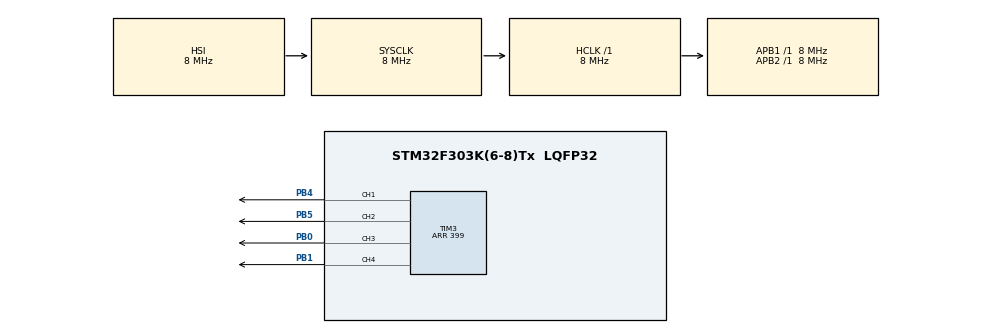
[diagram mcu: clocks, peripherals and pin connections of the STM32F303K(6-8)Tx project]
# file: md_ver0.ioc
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Mcu.Family=STM32F3
Mcu.Name=STM32F303K(6-8)Tx
Mcu.Package=LQFP32
NVIC.PriorityGroup=NVIC_PRIORITYGROUP_4
PB0.Signal=S_TIM3_CH3
PB1.Signal=S_TIM3_CH4
PB4.Signal=S_TIM3_CH1
PB5.Signal=S_TIM3_CH2
ProjectManager.HeapSize=0x200
ProjectManager.StackSize=0x400
ProjectManager.TargetToolchain=STM32CubeIDE
RCC.AHBFreq_Value=8000000
RCC.APB1Freq_Value=8000000
RCC.APB2Freq_Value=8000000
RCC.CortexFreq_Value=8000000
RCC.HSE_VALUE=8000000
RCC.HSI_VALUE=8000000
RCC.SYSCLKFreq_VALUE=8000000
SH.S_TIM3_CH1.0=TIM3_CH1,PWM Generation1 CH1
SH.S_TIM3_CH2.0=TIM3_CH2,PWM Generation2 CH2
SH.S_TIM3_CH3.0=TIM3_CH3,PWM Generation3 CH3
SH.S_TIM3_CH4.0=TIM3_CH4,PWM Generation4 CH4
TIM3.AutoReloadPreload=TIM_AUTORELOAD_PRELOAD_ENABLE
TIM3.Channel-PWM\ Generation1\ CH1=TIM_CHANNEL_1
TIM3.Channel-PWM\ Generation2\ CH2=TIM_CHANNEL_2
TIM3.Channel-PWM\ Generation3\ CH3=TIM_CHANNEL_3
TIM3.Channel-PWM\ Generation4\ CH4=TIM_CHANNEL_4
TIM3.CounterMode=TIM_COUNTERMODE_CENTERALIGNED3
TIM3.OCMode_PWM-PWM\ Generation3\ CH3=TIM_OCMODE_PWM2
TIM3.OCMode_PWM-PWM\ Generation4\ CH4=TIM_OCMODE_PWM1
TIM3.Period=399
board=custom

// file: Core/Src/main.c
/* USER CODE BEGIN Header */
/**
  ******************************************************************************
  * @file           : main.c
  * @brief          : Main program body
  ******************************************************************************
  * @attention
  *
  * Copyright (c) 2024 STMicroelectronics.
  * All rights reserved.
  *
  * This software is licensed under terms that can be found in the LICENSE file
  * in the root directory of this software component.
  * If no LICENSE file comes with this software, it is provided AS-IS.
  *
  ******************************************************************************
  */
/* USER CODE END Header */
#include "main.h"
#include "tim.h"
#include "gpio.h"

void SystemClock_Config(void);

int main(void)
{

  /* MCU Configuration--------------------------------------------------------*/

  /* Reset of all peripherals, Initializes the Flash interface and the Systick. */
  HAL_Init();

  /* Configure the system clock */
  SystemClock_Config();

  /* Initialize all configured peripherals */
  MX_GPIO_Init();
  MX_TIM3_Init();
  /* USER CODE BEGIN 2 */
//
//  int high = 300;
//  int low = 100;

  HAL_TIM_PWM_Start(&htim3, TIM_CHANNEL_1);
  HAL_TIM_PWM_Start(&htim3, TIM_CHANNEL_2);
  HAL_TIM_PWM_Start(&htim3, TIM_CHANNEL_3);
  HAL_TIM_PWM_Start(&htim3, TIM_CHANNEL_4);

  __HAL_TIM_SET_COMPARE(&htim3, TIM_CHANNEL_1, 0);
  __HAL_TIM_SET_COMPARE(&htim3, TIM_CHANNEL_2, 0);
  __HAL_TIM_SET_COMPARE(&htim3, TIM_CHANNEL_3, 0);
  __HAL_TIM_SET_COMPARE(&htim3, TIM_CHANNEL_3, 0);

  /* USER CODE END 2 */

  /* Infinite loop */
  /* USER CODE BEGIN WHILE */
  while (1)
  {
	  __HAL_TIM_SET_COMPARE(&htim3, TIM_CHANNEL_1, 0);
	  __HAL_TIM_SET_COMPARE(&htim3, TIM_CHANNEL_2, 399);
	  __HAL_TIM_SET_COMPARE(&htim3, TIM_CHANNEL_3, 60);
	  __HAL_TIM_SET_COMPARE(&htim3, TIM_CHANNEL_4, 40);

	  HAL_Delay(2000);
//
//	  __HAL_TIM_SET_COMPARE(&htim3, TIM_CHANNEL_1, 0);
//	  __HAL_TIM_SET_COMPARE(&htim3, TIM_CHANNEL_2, 80);
//	  __HAL_TIM_SET_COMPARE(&htim3, TIM_CHANNEL_3, 80);
//	  __HAL_TIM_SET_COMPARE(&htim3, TIM_CHANNEL_4, 0);
//
//	  HAL_Delay(2000);
//
//	  __HAL_TIM_SET_COMPARE(&htim3, TIM_CHANNEL_1, 0);
//	  __HAL_TIM_SET_COMPARE(&htim3, TIM_CHANNEL_2, 120);
//	  __HAL_TIM_SET_COMPARE(&htim3, TIM_CHANNEL_3, 120);
//	  __HAL_TIM_SET_COMPARE(&htim3, TIM_CHANNEL_4, 0);
//
//	  HAL_Delay(2000);
//
//	  __HAL_TIM_SET_COMPARE(&htim3, TIM_CHANNEL_1, 0);
//	  __HAL_TIM_SET_COMPARE(&htim3, TIM_CHANNEL_2, 160);
//	  __HAL_TIM_SET_COMPARE(&htim3, TIM_CHANNEL_3, 160);
//	  __HAL_TIM_SET_COMPARE(&htim3, TIM_CHANNEL_4, 0);
//
//	  HAL_Delay(2000);
//
//	  __HAL_TIM_SET_COMPARE(&htim3, TIM_CHANNEL_1, 0);
//	  __HAL_TIM_SET_COMPARE(&htim3, TIM_CHANNEL_2, 200);
//	  __HAL_TIM_SET_COMPARE(&htim3, TIM_CHANNEL_3, 200);
//	  __HAL_TIM_SET_COMPARE(&htim3, TIM_CHANNEL_4, 0);
//
//	  HAL_Delay(2000);
//
//	  __HAL_TIM_SET_COMPARE(&htim3, TIM_CHANNEL_1, 0);
//	  __HAL_TIM_SET_COMPARE(&htim3, TIM_CHANNEL_2, 240);
//	  __HAL_TIM_SET_COMPARE(&htim3, TIM_CHANNEL_3, 240);
//	  __HAL_TIM_SET_COMPARE(&htim3, TIM_CHANNEL_4, 0);
//
//	  HAL_Delay(2000);
//
//	  __HAL_TIM_SET_COMPARE(&htim3, TIM_CHANNEL_1, 0);
//	  __HAL_TIM_SET_COMPARE(&htim3, TIM_CHANNEL_2, 280);
//	  __HAL_TIM_SET_COMPARE(&htim3, TIM_CHANNEL_3, 280);
//	  __HAL_TIM_SET_COMPARE(&htim3, TIM_CHANNEL_4, 0);
//
//	  HAL_Delay(2000);
//
//	  __HAL_TIM_SET_COMPARE(&htim3, TIM_CHANNEL_1, 0);
//	  __HAL_TIM_SET_COMPARE(&htim3, TIM_CHANNEL_2, 320);
//	  __HAL_TIM_SET_COMPARE(&htim3, TIM_CHANNEL_3, 320);
//	  __HAL_TIM_SET_COMPARE(&htim3, TIM_CHANNEL_4, 0);
//
//	  HAL_Delay(2000);
//

    /* USER CODE END WHILE */

  }
}

void SystemClock_Config(void)
{
  RCC_OscInitTypeDef RCC_OscInitStruct = {0};
  RCC_ClkInitTypeDef RCC_ClkInitStruct = {0};

  /** Initializes the RCC Oscillators according to the specified parameters
  * in the RCC_OscInitTypeDef structure.
  */
  RCC_OscInitStruct.OscillatorType = RCC_OSCILLATORTYPE_HSI;
  RCC_OscInitStruct.HSIState = RCC_HSI_ON;
  RCC_OscInitStruct.HSICalibrationValue = RCC_HSICALIBRATION_DEFAULT;
  RCC_OscInitStruct.PLL.PLLState = RCC_PLL_NONE;
  if (HAL_RCC_OscConfig(&RCC_OscInitStruct) != HAL_OK)
  {
    Error_Handler();
  }

  /** Initializes the CPU, AHB and APB buses clocks
  */
  RCC_ClkInitStruct.ClockType = RCC_CLOCKTYPE_HCLK|RCC_CLOCKTYPE_SYSCLK
                              |RCC_CLOCKTYPE_PCLK1|RCC_CLOCKTYPE_PCLK2;
  RCC_ClkInitStruct.SYSCLKSource = RCC_SYSCLKSOURCE_HSI;
  RCC_ClkInitStruct.AHBCLKDivider = RCC_SYSCLK_DIV1;
  RCC_ClkInitStruct.APB1CLKDivider = RCC_HCLK_DIV1;
  RCC_ClkInitStruct.APB2CLKDivider = RCC_HCLK_DIV1;

  if (HAL_RCC_ClockConfig(&RCC_ClkInitStruct, FLASH_LATENCY_0) != HAL_OK)
  {
    Error_Handler();
  }
}

void Error_Handler(void)
{
  __disable_irq();
  while (1)
  {
  }
}
